VERSION "created by canmatrix"

NS_ :

BS_:

BU_: PKE DTU ESL OBC ABS BCU BMS VIU

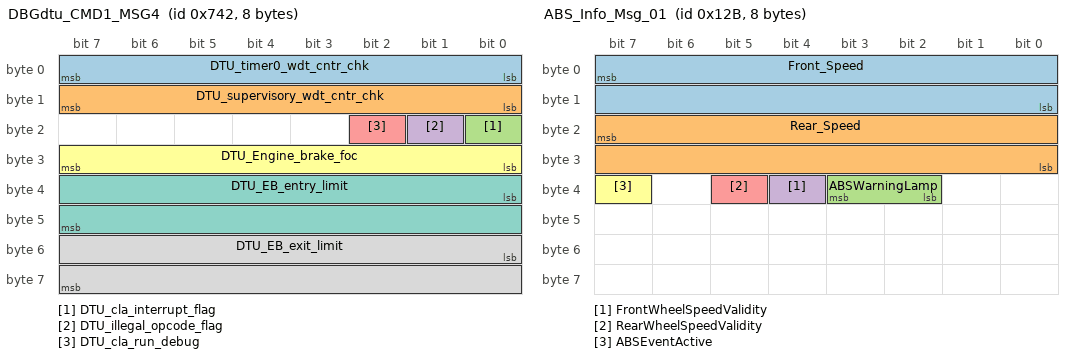
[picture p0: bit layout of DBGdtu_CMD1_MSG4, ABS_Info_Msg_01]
BO_ 1858 DBGdtu_CMD1_MSG4: 8 DTU
 SG_ DTU_timer0_wdt_cntr_chk : 0|8@1+ (1,0) [0|255] "count" VIU
 SG_ DTU_supervisory_wdt_cntr_chk : 8|8@1+ (1,0) [0|255] "count" VIU
 SG_ DTU_cla_interrupt_flag : 16|1@1+ (1,0) [0|1] "count" VIU
 SG_ DTU_illegal_opcode_flag : 17|1@1+ (1,0) [0|1] "count" VIU
 SG_ DTU_cla_run_debug : 18|1@1+ (1,0) [0|1] "count" VIU
 SG_ DTU_Engine_brake_foc : 24|8@1+ (1,0) [0|255] "count" VIU
 SG_ DTU_EB_entry_limit : 32|16@1+ (1,0) [0|65535] "rpm" VIU
 SG_ DTU_EB_exit_limit : 48|16@1+ (1,0) [0|65535] "rpm" VIU

BO_ 299 ABS_Info_Msg_01: 8 ABS
 SG_ Front_Speed : 7|16@0+ (0.05625,0) [0|65535] "kph" BCU,BMS,DTU,VIU
 SG_ Rear_Speed : 23|16@0+ (0.05625,0) [0|65535] "kph" BCU,BMS,DTU,VIU
 SG_ ABSWarningLamp : 35|2@0+ (1,0) [0|3] "State" BCU,BMS,DTU,VIU
 SG_ FrontWheelSpeedValidity : 36|1@0+ (1,0) [0|1] "Status" BCU,BMS,DTU,VIU
 SG_ RearWheelSpeedValidity : 37|1@0+ (1,0) [0|1] "Status" BCU,BMS,DTU,VIU
 SG_ ABSEventActive : 39|1@0+ (1,0) [0|1] "Status" BCU,BMS,DTU,VIU

VAL_ 299 ABSWarningLamp 0 "ABS_OK" 1 "ABS_FAULT" 2 "NA" 3 "NA";
VAL_ 299 FrontWheelSpeedValidity 0 "Normal" 1 "Failure";
VAL_ 299 RearWheelSpeedValidity 0 "Normal" 1 "Failure";
VAL_ 299 ABSEventActive 0 "Inactive" 1 "Active";
